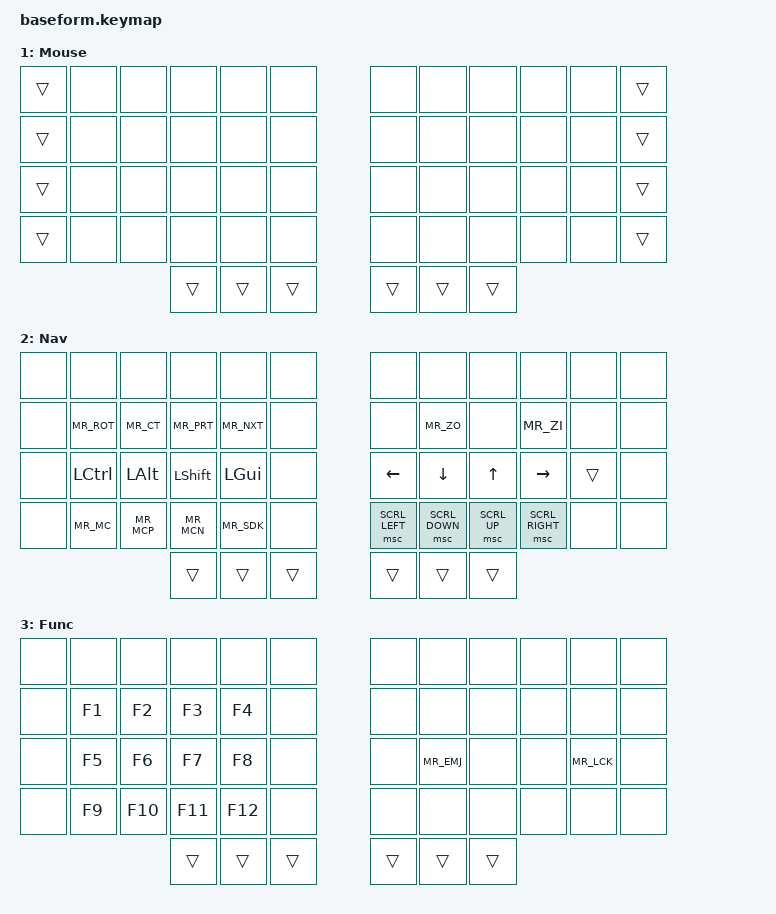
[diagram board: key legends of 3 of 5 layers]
#include <behaviors.dtsi>
#include <dt-bindings/zmk/keys.h>
#include <dt-bindings/zmk/bt.h>
#include <dt-bindings/zmk/ext_power.h>
#include <dt-bindings/zmk/outputs.h>
#include <dt-bindings/zmk/pointing.h>
// #include "../layer_defs.dtsi"
// #include "../keymap_edges.dtsi"

#define QWE 0
#define MSE 1
#define NAV 2
#define FUN 3
#define SYM 4

#define XXXXXX &none
#define ______ &trans
#define HRM_L(k1, k2, k3, k4) &htl LCTRL k1 &htl LALT k2   &htl LSHIFT k3 &htl LGUI k4
#define HRM_R(k1, k2, k3, k4) &htr LGUI k1  &htr LSHIFT k2 &htr RALT k3   &htr LCTRL k4
#define TBL_1 &kp SPACE
#define TBL_2 &lt NAV ESC
#define TBL_3 &mt LC(LALT) SPACE
#define TBR_1 &lt FUN RET
#define TBR_2 &mo SYM 
#define TBR_3 &kp CAPS
#define MSC_UP &msc SCRL_UP
#define MSC_DOWN &msc SCRL_DOWN
#define MSC_LEFT &msc SCRL_LEFT
#define MSC_RIGHT &msc SCRL_RIGHT

#define MR_RT LS(LG(R)) // Reload Tab
#define MR_CT LG(W) // Close Tab
#define MR_PRT LA(LG(LEFT)) // Previous Tab
#define MR_NXT LA(LG(RIGHT)) // Next Tab
#define MR_ROT LS(LG(T)) // Re-open Tab
#define MR_ZI LG(PLUS) // Zoom in
#define MR_ZO LG(MINUS) // Zoom out
#define MR_SC LS(LG(N2)) // Screenshot
#define MR_UN LG(Z) // Undo
#define MR_RD LS(LG(Z)) // Redo
#define MR_F LG(F) // Find
#define MR_CPY LG(C) // Copy
#define MR_CUT LG(X) // Cut
#define MR_PST LG(V) // Paste
#define MR_EMJ LC(LG(SPACE)) // Emoji
#define MR_LCK LC(LG(Q)) // Lock
#define MR_SDK LC(LA(O)) // Show Desktop
#define MR_MC LC(LA(P)) // Mission Control
#define MR_MCP LC(LA(J)) // Move Previous Window
#define MR_MCN LC(LA(K)) // Move Next Window
#define MR_SA LG(GRAVE) // Switch App

&lt {
  tapping-term-ms = <160>;
  quick_tap_ms = <160>;
};

&soft_off {
    hold-time-ms = <2000>; 
};

/ {

  behaviors {
    htl: ht_left {
      compatible = "zmk,behavior-hold-tap";
      #binding-cells = <2>;
      bindings = <&kp>,  <&kp>;

      flavor = "balanced";
      tapping-term-ms = <160>;
      quick-tap-ms = <175>;
      require-prior-idle-ms = <60>;

      hold-trigger-key-positions = <
        6  7  8  9  10 11
        18 19 20 21 22 23
        30 31 32 33 34 35
        42 43 44 45 46 47
        51 52 53
      >;
      hold-trigger-on-release;
    };

    htr: ht_right {
      compatible = "zmk,behavior-hold-tap";
      #binding-cells = <2>;
      bindings = <&kp>, <&kp>;

      flavor = "balanced";
      tapping-term-ms = <160>;
      quick-tap-ms = <175>;
      require-prior-idle-ms = <60>;

      hold-trigger-key-positions = <
        0  1  2  3  4  5
        12 13 14 15 16 17
        24 25 26 27 28 29
        36 37 38 39 40 41
        48 49 50
      >;
      hold-trigger-on-release;
    };

    mt: mod_tap {
      compatible = "zmk,behavior-hold-tap";
      #binding-cells = <2>;
      flavor = "tap-preferred";
      tapping-term-ms = <200>;
      quick-tap-ms = <175>;
      bindings = <&kp>, <&kp>;
      display-name = "Mod-Tap";
    };
  };

  combos {
    compatible = "zmk,combos";
    
    // Left hand combos
    combo_we {
      timeout-ms = <50>;
      key-positions = <14 15>;  // W E
      bindings = <&kp MR_UN>;
    };
    
    combo_er {
      timeout-ms = <50>;
      key-positions = <15 16>;  // E R
      bindings = <&kp MR_RD>;
    };
    
    combo_wr {
      timeout-ms = <50>;
      key-positions = <14 16>;  // W R
      bindings = <&kp MR_F>;
    };

    combo_as {
      timeout-ms = <50>;
      key-positions = <25 26>;  // A S
      bindings = <&kp RET>;
    };
    
    combo_sd {
      timeout-ms = <50>;
      key-positions = <26 27>;  // S D
      bindings = <&kp TAB>;
    };
    
    combo_df {
      timeout-ms = <50>;
      key-positions = <27 28>;  // D F
      bindings = <&kp BSPC>;
    };
    
    combo_sf {
      timeout-ms = <50>;
      key-positions = <26 28>;  // S F
      bindings = <&kp MR_SA>;
    };
    
    combo_xc {
      timeout-ms = <50>;
      key-positions = <38 39>;  // X C
      bindings = <&kp MR_CPY>;
    };
    
    combo_cv {
      timeout-ms = <50>;
      key-positions = <39 40>;  // C V
      bindings = <&kp MR_CUT>;
    };
    
    combo_xv {
      timeout-ms = <50>;
      key-positions = <38 40>;  // X V
      bindings = <&kp MR_PST>;
    };

    combo_se {
      timeout-ms = <50>;
      key-positions = <26 15>;  // S E
      bindings = <&kp MR_RT>;
    };

    combo_ef {
      timeout-ms = <50>;
      key-positions = <15 28>;  // E F
      bindings = <&kp MR_SC>;
    };

    combo_xd {
      timeout-ms = <50>;
      key-positions = <38 27>;  // X D
      bindings = <&kp F3>;
    };

    combo_dv {
      timeout-ms = <50>;
      key-positions = <27 40>;  // D V
      bindings = <&kp F12>;
    };
    
    // Right hand combos
    combo_ui {
      timeout-ms = <50>;
      key-positions = <19 20>;  // U I
      bindings = <&kp UNDER>;
    };
    
    combo_io {
      timeout-ms = <50>;
      key-positions = <20 21>;  // I O
      bindings = <&kp DLLR>;
    };
    
    combo_uo {
      timeout-ms = <50>;
      key-positions = <19 21>;  // U O
      bindings = <&kp GRAVE>;
    };
    
    combo_jk {
      timeout-ms = <50>;
      key-positions = <31 32>;  // J K
      bindings = <&kp SQT>;
    };
    
    combo_kl {
      timeout-ms = <50>;
      key-positions = <32 33>;  // K L
      bindings = <&kp DQT>;
    };
    
    combo_jl {
      timeout-ms = <50>;
      key-positions = <31 33>;  // J L
      bindings = <&kp COLON>;
    };
    
    combo_mcomm {
      timeout-ms = <50>;
      key-positions = <43 44>;  // M COMMA
      bindings = <&kp HASH>;
    };
    
    combo_commdot {
      timeout-ms = <50>;
      key-positions = <44 45>;  // COMMA DOT
      bindings = <&kp STAR>;
    };
    
    combo_mdot {
      timeout-ms = <50>;
      key-positions = <43 45>;  // M DOT
      bindings = <&kp SEMI>;
    };

    combo_ji {
      timeout-ms = <50>;
      key-positions = <31 20>;  // J I
      bindings = <&kp AMPS>;
    };

    combo_il {
      timeout-ms = <50>;
      key-positions = <20 33>;  // I L
      bindings = <&kp PIPE>;
    };

    combo_mk {
      timeout-ms = <50>;
      key-positions = <43 32>;  // M K
      bindings = <&kp LEFT>;
    };

    combo_kdot {
      timeout-ms = <50>;
      key-positions = <32 45>;  // K DOT
      bindings = <&kp RIGHT>;
    };
  };

  keymap {
    compatible = "zmk,keymap";

    base {
      display-name = "Base";
      bindings = <
        //╭──────────┬──────────┬──────────┬──────────┬──────────┬──────────╮   ╭──────────┬──────────┬──────────┬──────────┬──────────┬──────────╮
            XXXXXX     XXXXXX     XXXXXX     XXXXXX     XXXXXX     XXXXXX         XXXXXX     XXXXXX     XXXXXX     XXXXXX     XXXXXX     XXXXXX
        //├──────────┼──────────┼──────────┼──────────┼──────────┼──────────┤   ├──────────┼──────────┼──────────┼──────────┼──────────┼──────────┤
            XXXXXX     &kp Q      &kp W      &kp E      &kp R      &kp T          &kp Y      &kp U      &kp I      &kp O      &kp P      XXXXXX
        //├──────────┼──────────┼──────────┼──────────┼──────────┼──────────┤   ├──────────┼──────────┼──────────┼──────────┼──────────┼──────────┤
            XXXXXX     HRM_L(A,   S,         D,         F)         &kp G          &kp H      HRM_R(J,   K,         L,         BSPC)      XXXXXX
        //├──────────┼──────────┼──────────┼──────────┼──────────┼──────────┤   ├──────────┼──────────┼──────────┼──────────┼──────────┼──────────┤
            XXXXXX     &kp Z      &kp X      &kp C      &kp V      &kp B          &kp N      &kp M      &kp COMMA  &kp DOT    &kp SLASH  XXXXXX
        //╰──────────┴──────────┴──────────┴──────────┼──────────┼──────────┤   ├──────────┼──────────┼──────────┴──────────┴──────────┴──────────╯
                                             TBL_1      TBL_2      TBL_3          TBR_1      TBR_2      TBR_3
        //                                 ╰──────────┴──────────┴──────────╯   ╰──────────┴──────────┴──────────╯
      >;
    };

    mouse {
      display-name = "Mouse";
      bindings = <
        //╭──────────┬──────────┬──────────┬──────────┬──────────┬──────────╮   ╭──────────┬──────────┬──────────┬──────────┬──────────┬──────────╮
            ______     XXXXXX     XXXXXX     XXXXXX     XXXXXX     XXXXXX         XXXXXX     XXXXXX     XXXXXX     XXXXXX     XXXXXX     ______
        //├──────────┼──────────┼──────────┼──────────┼──────────┼──────────┤   ├──────────┼──────────┼──────────┼──────────┼──────────┼──────────┤
            ______     XXXXXX     XXXXXX     XXXXXX     XXXXXX     XXXXXX         XXXXXX     XXXXXX     XXXXXX     XXXXXX     XXXXXX     ______
        //├──────────┼──────────┼──────────┼──────────┼──────────┼──────────┤   ├──────────┼──────────┼──────────┼──────────┼──────────┼──────────┤
            ______     XXXXXX     XXXXXX     XXXXXX     XXXXXX     XXXXXX         XXXXXX     XXXXXX     XXXXXX     XXXXXX     XXXXXX     ______
        //├──────────┼──────────┼──────────┼──────────┼──────────┼──────────┤   ├──────────┼──────────┼──────────┼──────────┼──────────┼──────────┤
            ______     XXXXXX     XXXXXX     XXXXXX     XXXXXX     XXXXXX         XXXXXX     XXXXXX     XXXXXX     XXXXXX     XXXXXX     ______
        //╰──────────┴──────────┴──────────┴──────────┼──────────┼──────────┤   ├──────────┼──────────┼──────────┴──────────┴──────────┴──────────╯
                                             ______     ______     ______         ______     ______     ______
        //                                 ╰──────────┴──────────┴──────────╯   ╰──────────┴──────────┴──────────╯
      >;
    };

    navigation {
      display-name = "Nav";
      bindings = <
        //╭──────────┬──────────┬──────────┬──────────┬──────────┬──────────╮   ╭──────────┬──────────┬──────────┬──────────┬──────────┬──────────╮
            XXXXXX     XXXXXX     XXXXXX     XXXXXX     XXXXXX     XXXXXX         XXXXXX     XXXXXX     XXXXXX     XXXXXX     XXXXXX     XXXXXX
        //├──────────┼──────────┼──────────┼──────────┼──────────┼──────────┤   ├──────────┼──────────┼──────────┼──────────┼──────────┼──────────┤
            XXXXXX     &kp MR_ROT &kp MR_CT  &kp MR_PRT &kp MR_NXT XXXXXX         XXXXXX     &kp MR_ZO  XXXXXX     &kp MR_ZI  XXXXXX     XXXXXX
        //├──────────┼──────────┼──────────┼──────────┼──────────┼──────────┤   ├──────────┼──────────┼──────────┼──────────┼──────────┼──────────┤
            XXXXXX     &kp LCTRL  &kp LALT   &kp LSHFT  &kp LGUI   XXXXXX         &kp LEFT   &kp DOWN   &kp UP     &kp RIGHT  ______     XXXXXX
        //├──────────┼──────────┼──────────┼──────────┼──────────┼──────────┤   ├──────────┼──────────┼──────────┼──────────┼──────────┼──────────┤
            XXXXXX     &kp MR_MC  &kp MR_MCP &kp MR_MCN &kp MR_SDK XXXXXX         MSC_LEFT   MSC_DOWN   MSC_UP     MSC_RIGHT  XXXXXX     XXXXXX
        //╰──────────┴──────────┴──────────┴──────────┼──────────┼──────────┤   ├──────────┼──────────┼──────────┴──────────┴──────────┴──────────╯
                                             ______     ______     ______         ______     ______     ______
        //                                 ╰──────────┴──────────┴──────────╯   ╰──────────┴──────────┴──────────╯
      >;
    };

    function {
      display-name = "Func";
      bindings = <
        //╭──────────┬──────────┬──────────┬──────────┬──────────┬──────────╮   ╭──────────┬──────────┬──────────┬──────────┬──────────┬──────────╮
            XXXXXX     XXXXXX     XXXXXX     XXXXXX     XXXXXX     XXXXXX         XXXXXX     XXXXXX     XXXXXX     XXXXXX     XXXXXX     XXXXXX
        //├──────────┼──────────┼──────────┼──────────┼──────────┼──────────┤   ├──────────┼──────────┼──────────┼──────────┼──────────┼──────────┤
            XXXXXX     &kp F1     &kp F2     &kp F3     &kp F4     XXXXXX         XXXXXX     XXXXXX     XXXXXX     XXXXXX     XXXXXX     XXXXXX
        //├──────────┼──────────┼──────────┼──────────┼──────────┼──────────┤   ├──────────┼──────────┼──────────┼──────────┼──────────┼──────────┤
            XXXXXX     &kp F5     &kp F6     &kp F7     &kp F8     XXXXXX         XXXXXX     &kp MR_EMJ XXXXXX     XXXXXX     &kp MR_LCK XXXXXX
        //├──────────┼──────────┼──────────┼──────────┼──────────┼──────────┤   ├──────────┼──────────┼──────────┼──────────┼──────────┼──────────┤
            XXXXXX     &kp F9     &kp F10    &kp F11    &kp F12    XXXXXX         XXXXXX     XXXXXX     XXXXXX     XXXXXX     XXXXXX     XXXXXX
        //╰──────────┴──────────┴──────────┴──────────┼──────────┼──────────┤   ├──────────┼──────────┼──────────┴──────────┴──────────┴──────────╯
                                             ______     ______     ______         ______     ______     ______
        //                                 ╰──────────┴──────────┴──────────╯   ╰──────────┴──────────┴──────────╯
      >;
    };

    symbols {	
      display-name = "Sym";
      bindings = <
        //╭──────────┬──────────┬──────────┬──────────┬──────────┬──────────╮   ╭──────────┬──────────┬──────────┬──────────┬──────────┬──────────╮
            XXXXXX     XXXXXX     XXXXXX     XXXXXX     XXXXXX     XXXXXX         XXXXXX     XXXXXX     XXXXXX     XXXXXX     XXXXXX     XXXXXX
        //├──────────┼──────────┼──────────┼──────────┼──────────┼──────────┤   ├──────────┼──────────┼──────────┼──────────┼──────────┼──────────┤
            XXXXXX     XXXXXX     &kp N1     &kp N2     &kp N3     XXXXXX         XXXXXX     &kp EXCL   &kp LBRC   &kp RBRC   &kp CARET   XXXXXX
        //├──────────┼──────────┼──────────┼──────────┼──────────┼──────────┤   ├──────────┼──────────┼──────────┼──────────┼──────────┼──────────┤
            XXXXXX     HRM_L(N0,  N4,        N5,        N6)        &kp AT         &kp PLUS   HRM_R(EQUAL,LPAR,     RPAR,      MINUS)     XXXXXX
        //├──────────┼──────────┼──────────┼──────────┼──────────┼──────────┤   ├──────────┼──────────┼──────────┼──────────┼──────────┼──────────┤
            XXXXXX     &kp TILD   &kp N7     &kp N8     &kp N9     XXXXXX         XXXXXX     &kp PRCNT  &kp LBKT   &kp RBKT   &kp BSLH   XXXXXX
        //╰──────────┴──────────┴──────────┴──────────┼──────────┼──────────┤   ├──────────┼──────────┼──────────┴──────────┴──────────┴──────────╯
                                             ______     ______     ______         ______     ______     ______
        //                                 ╰──────────┴──────────┴──────────╯   ╰──────────┴──────────┴──────────╯
      >;
    };
 
// #include "../shared_layers.dtsi"

    extra1 {
        status = "reserved";
    };

    extra2 {
        status = "reserved";
    };

    extra3 {
        status = "reserved";
    };

    extra4 {
        status = "reserved";
    };

    extra5 {
        status = "reserved";
    };
  };
};
